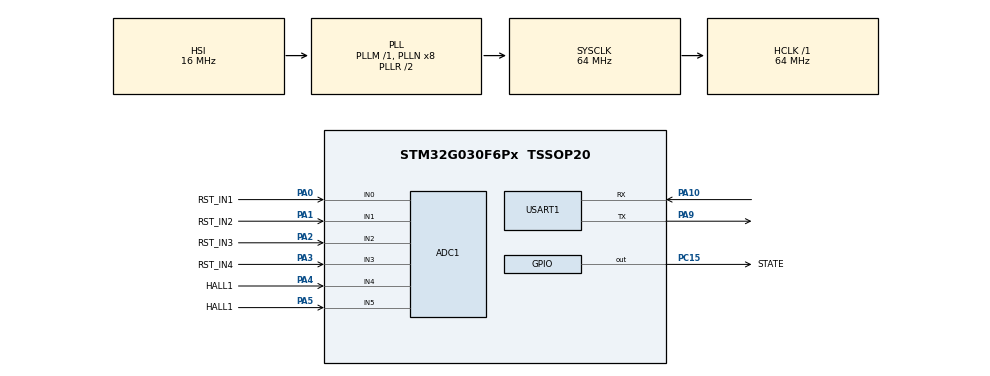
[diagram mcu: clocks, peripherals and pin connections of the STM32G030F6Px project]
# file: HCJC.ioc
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ADC1.Channel-1\#ChannelRegularConversion=ADC_CHANNEL_0
ADC1.Channel-10\#ChannelRegularConversion=ADC_CHANNEL_4
ADC1.Channel-11\#ChannelRegularConversion=ADC_CHANNEL_5
ADC1.Channel-7\#ChannelRegularConversion=ADC_CHANNEL_1
ADC1.Channel-8\#ChannelRegularConversion=ADC_CHANNEL_2
ADC1.Channel-9\#ChannelRegularConversion=ADC_CHANNEL_3
ADC1.ClockPrescaler=ADC_CLOCK_SYNC_PCLK_DIV4
ADC1.ContinuousConvMode=DISABLE
ADC1.DMAContinuousRequests=ENABLE
ADC1.EOCSelection=ADC_EOC_SINGLE_CONV
ADC1.ExternalTrigConv=ADC_EXTERNALTRIG_T3_TRGO
ADC1.NbrOfConversion=6
ADC1.NbrOfConversionFlag=1
ADC1.Rank-1\#ChannelRegularConversion=1
ADC1.Rank-10\#ChannelRegularConversion=5
ADC1.Rank-11\#ChannelRegularConversion=6
ADC1.Rank-7\#ChannelRegularConversion=2
ADC1.Rank-8\#ChannelRegularConversion=3
ADC1.Rank-9\#ChannelRegularConversion=4
ADC1.SamplingTime-1\#ChannelRegularConversion=ADC_SAMPLINGTIME_COMMON_1
ADC1.SamplingTime-10\#ChannelRegularConversion=ADC_SAMPLINGTIME_COMMON_1
ADC1.SamplingTime-11\#ChannelRegularConversion=ADC_SAMPLINGTIME_COMMON_1
ADC1.SamplingTime-7\#ChannelRegularConversion=ADC_SAMPLINGTIME_COMMON_1
ADC1.SamplingTime-8\#ChannelRegularConversion=ADC_SAMPLINGTIME_COMMON_1
ADC1.SamplingTime-9\#ChannelRegularConversion=ADC_SAMPLINGTIME_COMMON_1
ADC1.SamplingTimeCommon1=ADC_SAMPLETIME_12CYCLES_5
ADC1.SamplingTimeCommon2=ADC_SAMPLETIME_12CYCLES_5
ADC1.SelectedChannel=ADC_CHANNEL_0|ADC_CHANNEL_1|ADC_CHANNEL_2|ADC_CHANNEL_3|ADC_CHANNEL_4|ADC_CHANNEL_5
ADC1.TriggerFrequencyMode=ADC_TRIGGER_FREQ_HIGH
ADC1.master=1
Dma.ADC1.2.Direction=DMA_PERIPH_TO_MEMORY
Dma.ADC1.2.EventEnable=DISABLE
Dma.ADC1.2.Instance=DMA1_Channel3
Dma.ADC1.2.MemDataAlignment=DMA_MDATAALIGN_HALFWORD
Dma.ADC1.2.MemInc=DMA_MINC_ENABLE
Dma.ADC1.2.Mode=DMA_CIRCULAR
Dma.ADC1.2.PeriphDataAlignment=DMA_PDATAALIGN_HALFWORD
Dma.ADC1.2.PeriphInc=DMA_PINC_DISABLE
Dma.ADC1.2.Polarity=HAL_DMAMUX_REQ_GEN_RISING
Dma.ADC1.2.Priority=DMA_PRIORITY_MEDIUM
Dma.ADC1.2.RequestNumber=1
Dma.ADC1.2.SignalID=NONE
Dma.ADC1.2.SyncEnable=DISABLE
Dma.ADC1.2.SyncPolarity=HAL_DMAMUX_SYNC_NO_EVENT
Dma.ADC1.2.SyncRequestNumber=1
Dma.ADC1.2.SyncSignalID=NONE
Dma.Request0=USART1_RX
Dma.Request1=USART1_TX
Dma.Request2=ADC1
Dma.USART1_RX.0.Direction=DMA_PERIPH_TO_MEMORY
Dma.USART1_RX.0.EventEnable=DISABLE
Dma.USART1_RX.0.Instance=DMA1_Channel1
Dma.USART1_RX.0.MemDataAlignment=DMA_MDATAALIGN_BYTE
Dma.USART1_RX.0.MemInc=DMA_MINC_ENABLE
Dma.USART1_RX.0.Mode=DMA_CIRCULAR
Dma.USART1_RX.0.PeriphDataAlignment=DMA_PDATAALIGN_BYTE
Dma.USART1_RX.0.PeriphInc=DMA_PINC_DISABLE
Dma.USART1_RX.0.Polarity=HAL_DMAMUX_REQ_GEN_RISING
Dma.USART1_RX.0.Priority=DMA_PRIORITY_LOW
Dma.USART1_RX.0.RequestNumber=1
Dma.USART1_RX.0.SignalID=NONE
Dma.USART1_RX.0.SyncEnable=DISABLE
Dma.USART1_RX.0.SyncPolarity=HAL_DMAMUX_SYNC_NO_EVENT
Dma.USART1_RX.0.SyncRequestNumber=1
Dma.USART1_RX.0.SyncSignalID=NONE
Dma.USART1_TX.1.Direction=DMA_MEMORY_TO_PERIPH
Dma.USART1_TX.1.EventEnable=DISABLE
Dma.USART1_TX.1.Instance=DMA1_Channel2
Dma.USART1_TX.1.MemDataAlignment=DMA_MDATAALIGN_BYTE
Dma.USART1_TX.1.MemInc=DMA_MINC_ENABLE
Dma.USART1_TX.1.Mode=DMA_NORMAL
Dma.USART1_TX.1.PeriphDataAlignment=DMA_PDATAALIGN_BYTE
Dma.USART1_TX.1.PeriphInc=DMA_PINC_DISABLE
Dma.USART1_TX.1.Polarity=HAL_DMAMUX_REQ_GEN_RISING
Dma.USART1_TX.1.Priority=DMA_PRIORITY_LOW
Dma.USART1_TX.1.RequestNumber=1
Dma.USART1_TX.1.SignalID=NONE
Dma.USART1_TX.1.SyncEnable=DISABLE
Dma.USART1_TX.1.SyncPolarity=HAL_DMAMUX_SYNC_NO_EVENT
Dma.USART1_TX.1.SyncRequestNumber=1
Dma.USART1_TX.1.SyncSignalID=NONE
Mcu.Family=STM32G0
Mcu.Name=STM32G030F6Px
Mcu.Package=TSSOP20
NVIC.ADC1_IRQn=true\:0\:0\:false\:false\:true\:true\:true\:true
NVIC.DMA1_Channel1_IRQn=true\:0\:0\:false\:false\:true\:false\:true\:true
NVIC.DMA1_Channel2_3_IRQn=true\:0\:0\:false\:false\:true\:false\:true\:true
NVIC.TIM1_BRK_UP_TRG_COM_IRQn=true\:0\:0\:false\:false\:true\:true\:true\:true
NVIC.TIM1_CC_IRQn=true\:0\:0\:false\:false\:true\:true\:true\:true
NVIC.USART1_IRQn=true\:0\:0\:false\:false\:true\:true\:true\:true
PA0.GPIO_Label=RST_IN1
PA0.Mode=IN0
PA0.Signal=ADC1_IN0
PA1.GPIO_Label=RST_IN2
PA1.Mode=IN1
PA1.Signal=ADC1_IN1
PA10\ [PA12].Mode=Asynchronous
PA10\ [PA12].Signal=USART1_RX
PA13.Mode=Serial_Wire
PA13.Signal=SYS_SWDIO
PA14-BOOT0.Mode=Serial_Wire
PA14-BOOT0.Signal=SYS_SWCLK
PA14-BOOT0__PA15.StandardMode=true
PA2.GPIO_Label=RST_IN3
PA2.Mode=IN2
PA2.Signal=ADC1_IN2
PA3.GPIO_Label=RST_IN4
PA3.Mode=IN3
PA3.Signal=ADC1_IN3
PA4.GPIO_Label=HALL1
PA4.Mode=IN4
PA4.Signal=ADC1_IN4
PA5.GPIO_Label=HALL1
PA5.Mode=IN5
PA5.Signal=ADC1_IN5
PA9\ [PA11].Mode=Asynchronous
PA9\ [PA11].Signal=USART1_TX
PB0__PB1__PB2__PA8.StandardMode=true
PB3__PB4__PB5__PB6.StandardMode=true
PB7__PB8.StandardMode=true
PC14-OSC32_IN\ (PC14)__PB9.StandardMode=true
PC15-OSC32_OUT\ (PC15).GPIO_Label=STATE
PC15-OSC32_OUT\ (PC15).Signal=GPIO_Output
ProjectManager.HeapSize=0x400
ProjectManager.StackSize=0x800
ProjectManager.TargetToolchain=MDK-ARM V5.27
RCC.ADCFreq_Value=64000000
RCC.AHBFreq_Value=64000000
RCC.CortexFreq_Value=64000000
RCC.EXTERNAL_CLOCK_VALUE=12288000
RCC.HCLKFreq_Value=64000000
RCC.HSE_VALUE=8000000
RCC.HSI_VALUE=16000000
RCC.LSE_VALUE=32768
RCC.SYSCLKFreq_VALUE=64000000
RCC.SYSCLKSource=RCC_SYSCLKSOURCE_PLLCLK
RCC.VCOOutputFreq_Value=128000000
TIM1.AutoReloadPreload=TIM_AUTORELOAD_PRELOAD_ENABLE
TIM1.Period=9999
TIM1.Prescaler=6399
TIM3.AutoReloadPreload=TIM_AUTORELOAD_PRELOAD_ENABLE
TIM3.Period=5000
TIM3.Prescaler=6399
TIM3.TIM_MasterOutputTrigger=TIM_TRGO_UPDATE
TIM3.TIM_MasterSlaveMode=TIM_MASTERSLAVEMODE_DISABLE
USART1.VirtualMode-Asynchronous=VM_ASYNC
VP_CRC_VS_CRC.Mode=CRC_Activate
VP_SYS_VS_PINREMAP.Mode=PINREMAP
VP_SYS_VS_PINREMAP_10_12.Mode=PINREMAP_10_12
VP_TIM1_VS_ClockSourceINT.Mode=Internal
VP_TIM3_VS_ClockSourceINT.Mode=Internal
board=custom

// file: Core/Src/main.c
/* USER CODE BEGIN Header */
/**
  ******************************************************************************
  * @file           : main.c
  * @brief          : Main program body
  ******************************************************************************
  * @attention
  *
  * Copyright (c) 2023 STMicroelectronics.
  * All rights reserved.
  *
  * This software is licensed under terms that can be found in the LICENSE file
  * in the root directory of this software component.
  * If no LICENSE file comes with this software, it is provided AS-IS.
  *
  ******************************************************************************
  */
/* USER CODE END Header */
#include "main.h"
#include "adc.h"
#include "crc.h"
#include "dma.h"
#include "tim.h"
#include "usart.h"
#include "gpio.h"

/* USER CODE BEGIN Includes */
#include "modbus.h"
#include "usart_dispose.h"
/* USER CODE END Includes */

/* USER CODE BEGIN PTD */
extern UART_HandleTypeDef huart1;
extern uint16_t DMA_TATA_BUFFER[CONVERT_DMA_DATA];
/* USER CODE END PTD */

void SystemClock_Config(void);

/* USER CODE BEGIN 0 */

//Bob prev;
//uint8_t test[8] = {1,2,3,4,5,6,7,8};
/* USER CODE END 0 */

int main(void)
{

  /* MCU Configuration--------------------------------------------------------*/

  /* Reset of all peripherals, Initializes the Flash interface and the Systick. */
  HAL_Init();

  /* Configure the system clock */
  SystemClock_Config();

  /* Initialize all configured peripherals */
  MX_GPIO_Init();
  MX_DMA_Init();
  MX_ADC1_Init();
  MX_USART1_UART_Init();
  MX_TIM3_Init();
  MX_CRC_Init();
  MX_TIM1_Init();
  /* USER CODE BEGIN 2 */
    X_Start_IDLE_DMA();  /* 开启空闲中断接收 */
	HAL_ADCEx_Calibration_Start(&hadc1);//ADC自动校准
	HAL_Delay(100); //延时100ms
	HAL_ADC_Start_DMA(&hadc1,(uint32_t*)&DMA_TATA_BUFFER,CONVERT_DMA_DATA);
	HAL_TIM_Base_Start(&htim3);
	HAL_TIM_Base_Start_IT(&htim1);

  /* USER CODE END 2 */

  /* Infinite loop */
  while (1)
  {

  }
}

void SystemClock_Config(void)
{
  RCC_OscInitTypeDef RCC_OscInitStruct = {0};
  RCC_ClkInitTypeDef RCC_ClkInitStruct = {0};

  /** Configure the main internal regulator output voltage
  */
  HAL_PWREx_ControlVoltageScaling(PWR_REGULATOR_VOLTAGE_SCALE1);

  /** Initializes the RCC Oscillators according to the specified parameters
  * in the RCC_OscInitTypeDef structure.
  */
  RCC_OscInitStruct.OscillatorType = RCC_OSCILLATORTYPE_HSI;
  RCC_OscInitStruct.HSIState = RCC_HSI_ON;
  RCC_OscInitStruct.HSIDiv = RCC_HSI_DIV1;
  RCC_OscInitStruct.HSICalibrationValue = RCC_HSICALIBRATION_DEFAULT;
  RCC_OscInitStruct.PLL.PLLState = RCC_PLL_ON;
  RCC_OscInitStruct.PLL.PLLSource = RCC_PLLSOURCE_HSI;
  RCC_OscInitStruct.PLL.PLLM = RCC_PLLM_DIV1;
  RCC_OscInitStruct.PLL.PLLN = 8;
  RCC_OscInitStruct.PLL.PLLP = RCC_PLLP_DIV2;
  RCC_OscInitStruct.PLL.PLLR = RCC_PLLR_DIV2;
  if (HAL_RCC_OscConfig(&RCC_OscInitStruct) != HAL_OK)
  {
    Error_Handler();
  }

  /** Initializes the CPU, AHB and APB buses clocks
  */
  RCC_ClkInitStruct.ClockType = RCC_CLOCKTYPE_HCLK|RCC_CLOCKTYPE_SYSCLK
                              |RCC_CLOCKTYPE_PCLK1;
  RCC_ClkInitStruct.SYSCLKSource = RCC_SYSCLKSOURCE_PLLCLK;
  RCC_ClkInitStruct.AHBCLKDivider = RCC_SYSCLK_DIV1;
  RCC_ClkInitStruct.APB1CLKDivider = RCC_HCLK_DIV1;

  if (HAL_RCC_ClockConfig(&RCC_ClkInitStruct, FLASH_LATENCY_2) != HAL_OK)
  {
    Error_Handler();
  }
}

void Error_Handler(void)
{
  __disable_irq();
  while (1)
  {
  }
}
